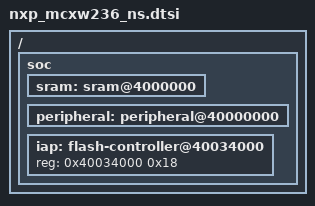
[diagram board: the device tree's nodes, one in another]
/*
 * Copyright 2025-2026 NXP
 *
 * SPDX-License-Identifier: Apache-2.0
 */

#include <mem.h>

/ {
	soc {
		sram: sram@4000000 {
			ranges = <0x4000000 0x4000000 DT_SIZE_K(16)>,
				 <0x20004000 0x20004000 DT_SIZE_K(112)>;
		};

		peripheral: peripheral@40000000 {
			ranges = <0x0 0x40000000 0x10000000>;
		};

		iap: flash-controller@40034000 {
			reg = <0x40034000 0x18>;
			ranges = <0x0 0x0 DT_SIZE_K(1016)>;
		};
	};
};

#include "nxp_mcxw23x_common.dtsi"
